# msmc register map
Vendor: Texas Instruments
Peripheral module from a debugger description file (folder Keystone2).
Registers are 32-bit, read-write, no defined reset value unless marked. A register's access mark holds for its fields unless they carry their own. Offsets are as the file gives them; lines under a group give offsets from that group; [hi:lo] are bit positions; {n}, {i} and the like mark numbered series; 'fields as' and 'values as' point back to an identical list; <NAME> marks a mode.

## MSMC
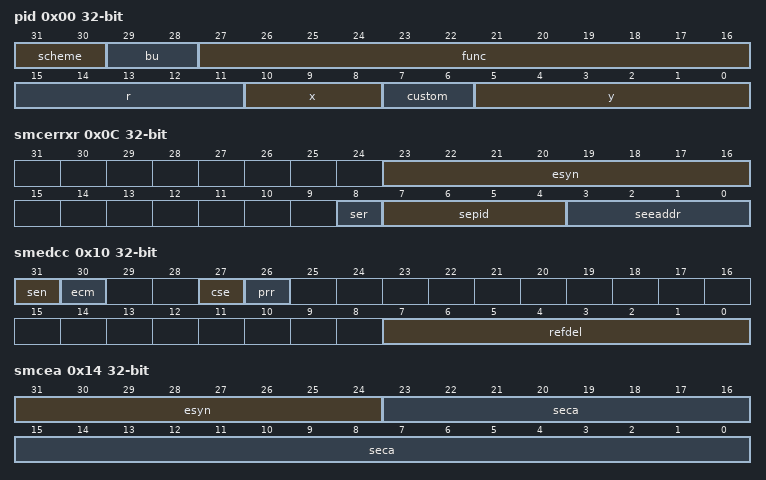
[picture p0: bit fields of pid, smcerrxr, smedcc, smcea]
0x00 pid
  [31:30] scheme, [29:28] bu, [27:16] func, [15:11] r, [10:8] x, [7:6] custom, [5:0] y
0x04 smcc
  [0] mcp
0x08 smcerrar
  [31:0] seaddr
0x0C smcerrxr
  [23:16] esyn, [8] ser, [7:4] sepid, [3:0] seeaddr
0x10 smedcc
  [31] sen, [30] ecm, [27] cse, [26] prr, [7:0] refdel
0x14 smcea
  [31:24] esyn, [23:0] seca
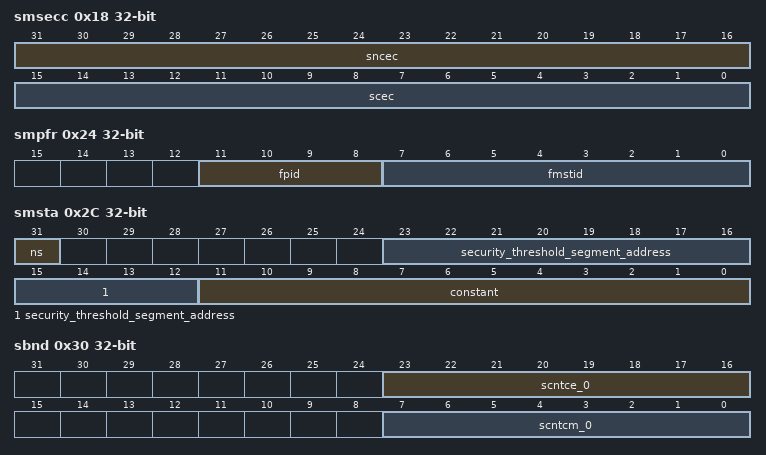
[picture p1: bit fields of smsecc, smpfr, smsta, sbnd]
0x18 smsecc
  [31:16] sncec, [15:0] scec
0x1C smpfar
  [31:0] fault_address
0x20 smpfxr
  [0] nm
0x24 smpfr
  [11:8] fpid, [7:0] fmstid
0x28 smpfcr
  [0] clr
0x2C smsta
  [31] ns, [23:12] security_threshold_segment_address, [11:0] constant
0x30 sbnd — (1 of 8, stride 4)
  [23:16] scntce_0, [7:0] scntcm_0
0x50 sbndm
  [7:0] scntmm
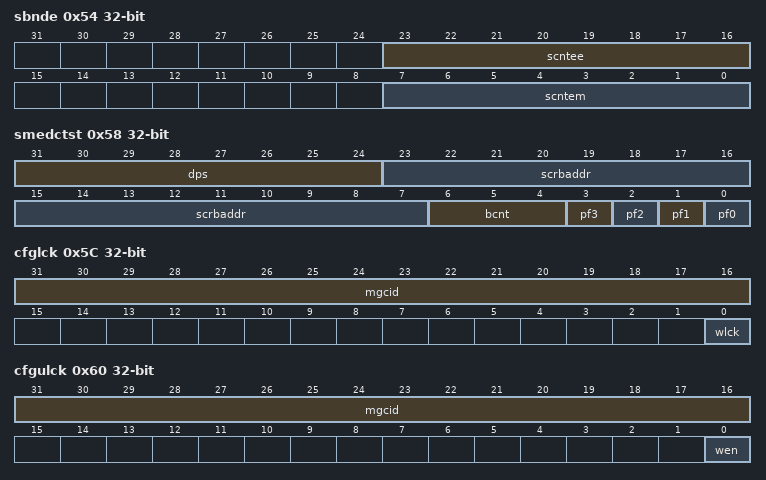
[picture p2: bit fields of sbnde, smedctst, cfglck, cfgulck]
0x54 sbnde
  [23:16] scntee, [7:0] scntem
0x58 smedctst
  [31:24] dps, [23:7] scrbaddr, [6:4] bcnt, [n] pf{n} (n=0..3)
0x5C cfglck
  [31:16] mgcid, [0] wlck
0x60 cfgulck
  [31:16] mgcid, [0] wen
0x64 cfglckstat
  [0] wstat
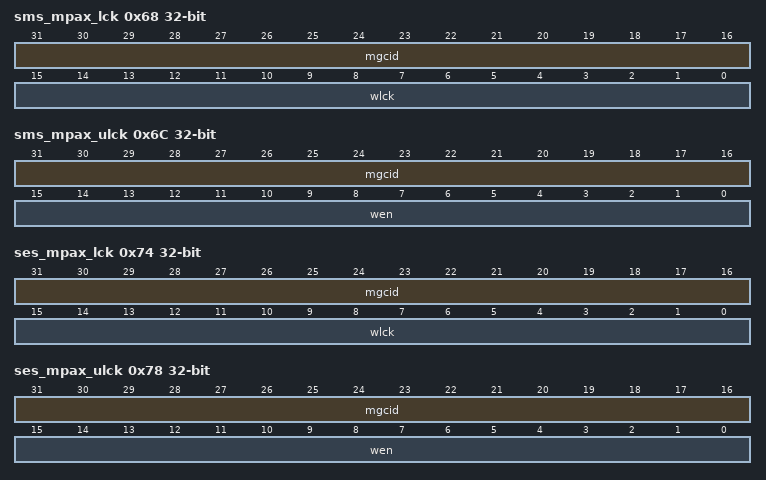
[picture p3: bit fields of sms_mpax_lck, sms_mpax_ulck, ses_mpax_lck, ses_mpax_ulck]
0x68 sms_mpax_lck
  [31:16] mgcid, [15:0] wlck
0x6C sms_mpax_ulck
  [31:16] mgcid, [15:0] wen
0x70 sms_mpax_lckstat
  [15:0] wstat
0x74 ses_mpax_lck
  [31:16] mgcid, [15:0] wlck
0x78 ses_mpax_ulck
  [31:16] mgcid, [15:0] wen
0x7C ses_mpax_lckstat
  [15:0] wstat
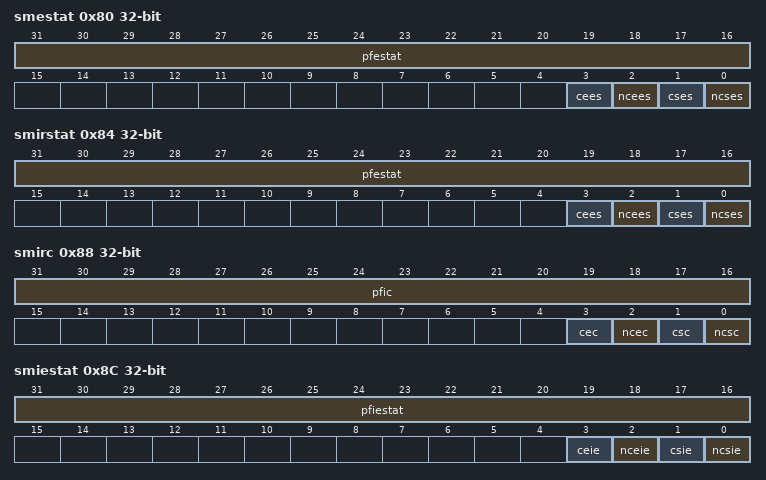
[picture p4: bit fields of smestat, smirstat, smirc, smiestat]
0x80 smestat
  [31:16] pfestat, [3] cees, [2] ncees, [1] cses, [0] ncses
0x84 smirstat
  [31:16] pfestat, [3] cees, [2] ncees, [1] cses, [0] ncses
0x88 smirc
  [31:16] pfic, [3] cec, [2] ncec, [1] csc, [0] ncsc
0x8C smiestat
  [31:16] pfiestat, [3] ceie, [2] nceie, [1] csie, [0] ncsie
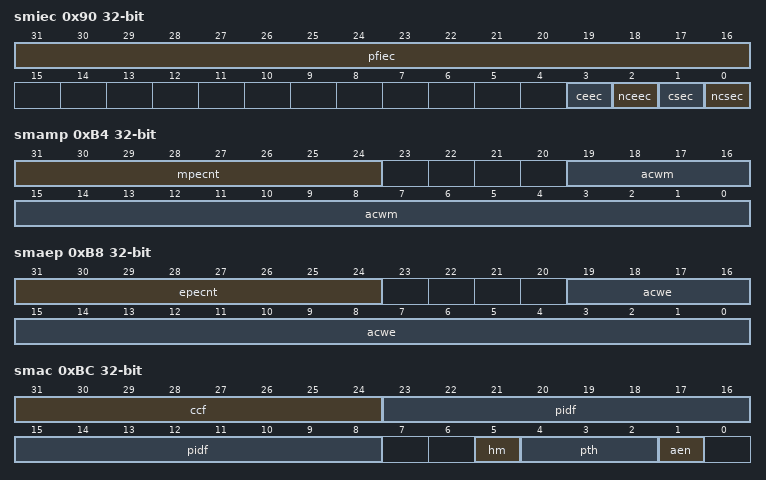
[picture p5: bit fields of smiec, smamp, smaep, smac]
0x90 smiec
  [31:16] pfiec, [3] ceec, [2] nceec, [1] csec, [0] ncsec
0xA0 smath
  [31:0] theader
0xA4 smah
  [19:0] hcnt
0xA8 smarm
  [19:0] rmcnt
0xAC smawm
  [19:0] wmcnt
0xB0 smav
  [19:0] vcnt
0xB4 smamp
  [31:24] mpecnt, [19:0] acwm
0xB8 smaep
  [31:24] epecnt, [19:0] acwe
0xBC smac
  [31:24] ccf, [23:8] pidf, [5] hm, [4:2] pth, [1] aen
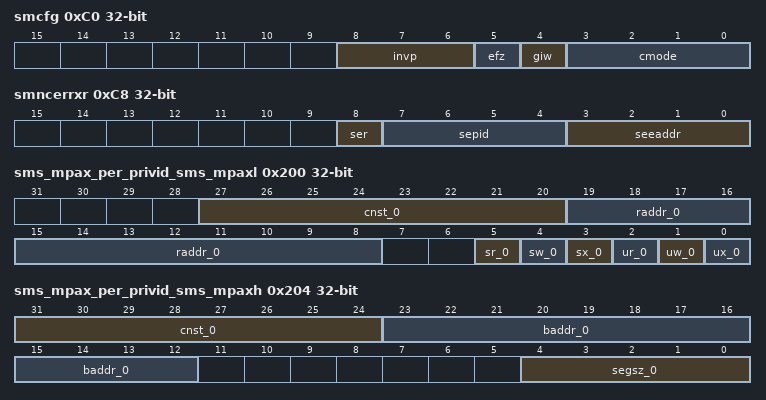
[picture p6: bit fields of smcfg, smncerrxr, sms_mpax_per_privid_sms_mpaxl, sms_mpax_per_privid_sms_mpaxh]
0xC0 smcfg
  [8:6] invp, [5] efz, [4] giw, [3:0] cmode
0xC4 smncerrar
  [31:0] seaddr
0xC8 smncerrxr
  [8] ser, [7:4] sepid, [3:0] seeaddr
0xCC smncea
  [23:0] senca
0x200 sms_mpax_per_privid_sms_mpaxl — (1 of 128, stride 8)
  [27:20] cnst_0, [19:8] raddr_0, [5] sr_0, [4] sw_0, [3] sx_0, [2] ur_0, [1] uw_0, [0] ux_0
0x204 sms_mpax_per_privid_sms_mpaxh — (1 of 128, stride 8)
  [31:24] cnst_0, [23:12] baddr_0, [4:0] segsz_0
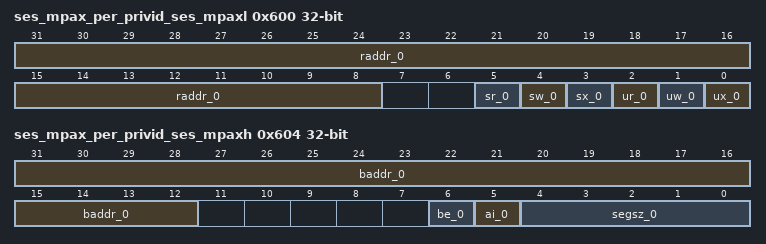
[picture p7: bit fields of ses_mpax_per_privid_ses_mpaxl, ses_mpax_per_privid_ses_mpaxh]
0x600 ses_mpax_per_privid_ses_mpaxl — (1 of 128, stride 8)
  [31:8] raddr_0, [5] sr_0, [4] sw_0, [3] sx_0, [2] ur_0, [1] uw_0, [0] ux_0
0x604 ses_mpax_per_privid_ses_mpaxh — (1 of 128, stride 8)
  [31:12] baddr_0, [6] be_0, [5] ai_0, [4:0] segsz_0
